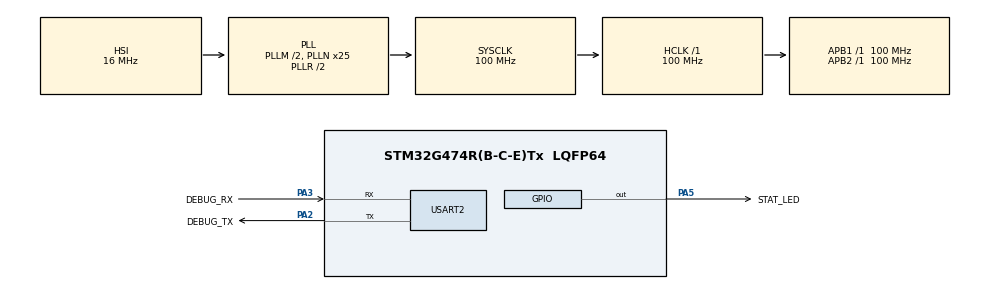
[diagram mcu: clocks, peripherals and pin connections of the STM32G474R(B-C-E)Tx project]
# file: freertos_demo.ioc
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Mcu.Family=STM32G4
Mcu.Name=STM32G474R(B-C-E)Tx
Mcu.Package=LQFP64
NVIC.PriorityGroup=NVIC_PRIORITYGROUP_4
NVIC.TIM6_DAC_IRQn=true\:15\:0\:false\:false\:true\:false\:true\:true
NVIC.TimeBase=TIM6_DAC_IRQn
NVIC.TimeBaseIP=TIM6
PA2.GPIO_Label=DEBUG_TX
PA2.Mode=Asynchronous
PA2.Signal=USART2_TX
PA3.GPIO_Label=DEBUG_RX
PA3.Mode=Asynchronous
PA3.Signal=USART2_RX
PA5.GPIO_Label=STAT_LED
PA5.Signal=GPIO_Output
ProjectManager.HeapSize=0x200
ProjectManager.StackSize=0x400
ProjectManager.TargetToolchain=STM32CubeIDE
RCC.ADC12Freq_Value=100000000
RCC.ADC345Freq_Value=100000000
RCC.AHBFreq_Value=100000000
RCC.APB1Freq_Value=100000000
RCC.APB1TimFreq_Value=100000000
RCC.APB2Freq_Value=100000000
RCC.APB2TimFreq_Value=100000000
RCC.CortexFreq_Value=100000000
RCC.EXTERNAL_CLOCK_VALUE=12288000
RCC.HCLKFreq_Value=100000000
RCC.HSE_VALUE=8000000
RCC.HSI48_VALUE=48000000
RCC.HSI_VALUE=16000000
RCC.LSE_VALUE=32768
RCC.PLLM=RCC_PLLM_DIV2
RCC.PLLN=25
RCC.SYSCLKFreq_VALUE=100000000
RCC.SYSCLKSource=RCC_SYSCLKSOURCE_PLLCLK
RCC.USBFreq_Value=100000000
RCC.VCOOutputFreq_Value=200000000
USART2.VirtualMode-Asynchronous=VM_ASYNC
VP_SYS_VS_DBSignals.Mode=DisableDeadBatterySignals
VP_SYS_VS_tim6.Mode=TIM6
board=custom

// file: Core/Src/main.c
/* USER CODE BEGIN Header */
/**
  ******************************************************************************
  * @file           : main.c
  * @brief          : Main program body
  ******************************************************************************
  * @attention
  *
  * Copyright (c) 2025 STMicroelectronics.
  * All rights reserved.
  *
  * This software is licensed under terms that can be found in the LICENSE file
  * in the root directory of this software component.
  * If no LICENSE file comes with this software, it is provided AS-IS.
  *
  ******************************************************************************
  */
/* USER CODE END Header */
#include "main.h"
#include "usart.h"
#include "gpio.h"

/* USER CODE BEGIN Includes */
#include <stdio.h>
#include "debug_serial.h"
#include "FreeRTOS.h"
#include "task.h"
#include "cmsis_os2.h"
/* USER CODE END Includes */

/* USER CODE BEGIN PD */
#define DWT_CTRL    (*(volatile uint32_t*)0xE0001000) //data watch point reg

/* USER CODE END PD */

/* USER CODE BEGIN PV */
static void task1_handler(void* parameters);
static void task2_handler(void* parameters);
/* USER CODE END PV */

void SystemClock_Config(void);

int main(void)
{

  /* USER CODE BEGIN 1 */
	TaskHandle_t task1_handle;
	TaskHandle_t task2_handle;

	BaseType_t status;

  /* USER CODE END 1 */

  /* MCU Configuration--------------------------------------------------------*/

  /* Reset of all peripherals, Initializes the Flash interface and the Systick. */
  HAL_Init();

  /* Configure the system clock */
  SystemClock_Config();

  /* Initialize all configured peripherals */
  MX_GPIO_Init();
  MX_USART2_UART_Init();
  /* USER CODE BEGIN 2 */

  //Enable the CYCCNT counter.
  DWT_CTRL |= ( 1 << 0);

//  SEGGER_UART_init(500000);

  SEGGER_SYSVIEW_Conf();
  SEGGER_SYSVIEW_Start();

  /*Create Tasks*/
  status = xTaskCreate(task1_handler, "Task-1", 200, "Hello world from Task-1", 2, &task1_handle);

  configASSERT(status == pdPASS);

  status = xTaskCreate(task2_handler, "Task-2", 200, "Hello world from Task-2", 2, &task2_handle);

  configASSERT(status == pdPASS);

  //start the freeRTOS scheduler
  vTaskStartScheduler();
  /* USER CODE END 2 */

  /* Infinite loop */
  /* USER CODE BEGIN WHILE */
  while (1)
  {
	  HAL_GPIO_TogglePin(STAT_LED_GPIO_Port, STAT_LED_Pin);
	  debug_print("Hello UART\n");
	  printf("Hello ITM\n");
	  HAL_Delay(200);

    /* USER CODE END WHILE */

  }
}

void SystemClock_Config(void)
{
  RCC_OscInitTypeDef RCC_OscInitStruct = {0};
  RCC_ClkInitTypeDef RCC_ClkInitStruct = {0};

  /** Configure the main internal regulator output voltage
  */
  HAL_PWREx_ControlVoltageScaling(PWR_REGULATOR_VOLTAGE_SCALE1);

  /** Initializes the RCC Oscillators according to the specified parameters
  * in the RCC_OscInitTypeDef structure.
  */
  RCC_OscInitStruct.OscillatorType = RCC_OSCILLATORTYPE_HSI;
  RCC_OscInitStruct.HSIState = RCC_HSI_ON;
  RCC_OscInitStruct.HSICalibrationValue = RCC_HSICALIBRATION_DEFAULT;
  RCC_OscInitStruct.PLL.PLLState = RCC_PLL_ON;
  RCC_OscInitStruct.PLL.PLLSource = RCC_PLLSOURCE_HSI;
  RCC_OscInitStruct.PLL.PLLM = RCC_PLLM_DIV2;
  RCC_OscInitStruct.PLL.PLLN = 25;
  RCC_OscInitStruct.PLL.PLLP = RCC_PLLP_DIV2;
  RCC_OscInitStruct.PLL.PLLQ = RCC_PLLQ_DIV2;
  RCC_OscInitStruct.PLL.PLLR = RCC_PLLR_DIV2;
  if (HAL_RCC_OscConfig(&RCC_OscInitStruct) != HAL_OK)
  {
    Error_Handler();
  }

  /** Initializes the CPU, AHB and APB buses clocks
  */
  RCC_ClkInitStruct.ClockType = RCC_CLOCKTYPE_HCLK|RCC_CLOCKTYPE_SYSCLK
                              |RCC_CLOCKTYPE_PCLK1|RCC_CLOCKTYPE_PCLK2;
  RCC_ClkInitStruct.SYSCLKSource = RCC_SYSCLKSOURCE_PLLCLK;
  RCC_ClkInitStruct.AHBCLKDivider = RCC_SYSCLK_DIV1;
  RCC_ClkInitStruct.APB1CLKDivider = RCC_HCLK_DIV1;
  RCC_ClkInitStruct.APB2CLKDivider = RCC_HCLK_DIV1;

  if (HAL_RCC_ClockConfig(&RCC_ClkInitStruct, FLASH_LATENCY_3) != HAL_OK)
  {
    Error_Handler();
  }
}

/* USER CODE BEGIN 4 */
static void task1_handler(void* parameters)
{
	while(1)
	{
		printf("%s\n", (char*)parameters);
//		vTaskDelay(2500);
	}

}

static void task2_handler(void* parameters)
{
	while(1)
	{
		printf("%s\n", (char*)parameters);
//		vTaskDelay(5000);

	}
}
/* USER CODE END 4 */

void HAL_TIM_PeriodElapsedCallback(TIM_HandleTypeDef *htim)
{
  if (htim->Instance == TIM6) {
    HAL_IncTick();
  }
}

void Error_Handler(void)
{
  __disable_irq();
  while (1)
  {
  }
}
